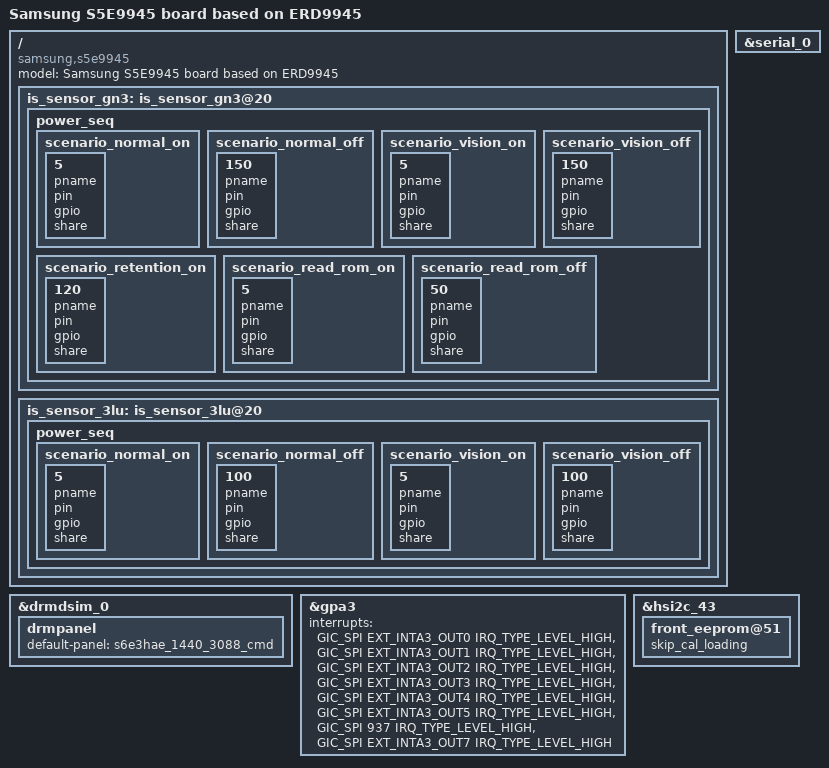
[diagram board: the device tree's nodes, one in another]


/*
 * SAMSUNG S5E9945 board device tree source
 *
 * Copyright (c) 2023 Samsung Electronics Co., Ltd.
 *		http://www.samsung.com
 *
 * This program is free software; you can redistribute it and/or modify
 * it under the terms of the GNU General Public License version 2 as
 * published by the Free Software Foundation.
 */

#include "s5e9945-b7r_pm_01.dtsi"
#include "s5e9945-b7r_common.dtsi"
#include "camera/s5e9945-b7r_camera.dtsi"
#include "s5e9945-b7r_bluetooth_00.dtsi"
#include "../../exynos/board/erd/panel/samsung-emulation-video-panel.dtsi"
#include "../../exynos/board/erd/panel/samsung-s6e3hae-1440-3088-command-panel.dtsi"
#include "s5e9945-b7r_wifi_01.dtsi"

/ {
	compatible = "samsung,s5e9945", "samsung,erd9945";

	fragment@model {
		target-path = "/";
		__overlay__ {
			#address-cells = <2>;
			#size-cells = <1>;

			model = "Samsung S5E9945 board based on ERD9945";
		}; /* end of __overlay__ */
	}; /* end of fragment */

	fragment@camera {
		target-path = "/";
		__overlay__ {

			is_sensor_gn3: is_sensor_gn3@20 {
				power_seq {
					scenario_normal_on {
						5 { pname; pin; gpio; share; };
					};
					scenario_normal_off {
						150 { pname; pin; gpio; share; };
					};
					scenario_vision_on {
						5 { pname; pin; gpio; share; };
					};
					scenario_vision_off {
						150 { pname; pin; gpio; share; };
					};
					scenario_retention_on {
						120 { pname; pin; gpio; share; };
					};
					scenario_read_rom_on {
						5 { pname; pin; gpio; share; };
					};
					scenario_read_rom_off {
						50 { pname; pin; gpio; share; };
					};
				};
			};

			is_sensor_3lu: is_sensor_3lu@20 {
				power_seq {
					scenario_normal_on {
						5 { pname; pin; gpio; share; };
					};
					scenario_normal_off {
						100 { pname; pin; gpio; share; };
					};
					scenario_vision_on {
						5 { pname; pin; gpio; share; };
					};
					scenario_vision_off {
						100 { pname; pin; gpio; share; };
					};
				};
			};
		};
	};
}; /* end of root */

&serial_0 {
	status = "okay";
};

&drmdsim_0 {
	drmpanel {
		default-panel = "s6e3hae_1440_3088_cmd";
	};
};

&gpa3 {
	interrupts = <GIC_SPI EXT_INTA3_OUT0 IRQ_TYPE_LEVEL_HIGH>, <GIC_SPI EXT_INTA3_OUT1 IRQ_TYPE_LEVEL_HIGH>,
				 <GIC_SPI EXT_INTA3_OUT2 IRQ_TYPE_LEVEL_HIGH>, <GIC_SPI EXT_INTA3_OUT3 IRQ_TYPE_LEVEL_HIGH>,
				 <GIC_SPI EXT_INTA3_OUT4 IRQ_TYPE_LEVEL_HIGH>, <GIC_SPI EXT_INTA3_OUT5 IRQ_TYPE_LEVEL_HIGH>,
				 <GIC_SPI 937 IRQ_TYPE_LEVEL_HIGH>, <GIC_SPI EXT_INTA3_OUT7 IRQ_TYPE_LEVEL_HIGH>;
};

&hsi2c_43 {
	front_eeprom@51 {
		skip_cal_loading;
	};
};
